# RockChip_RK3588 register map
Vendor: RockChip Electronics Co., Ltd.; Series: RK3588; File version: 0.1
Registers are 32-bit, read-write, no defined reset value unless marked. A register's access mark holds for its fields unless they carry their own. Offsets are from the block's base; [hi:lo] are bit positions; {n}, {i} and the like mark numbered series.

## IOC_PMU2
Base 0xFD5F4000
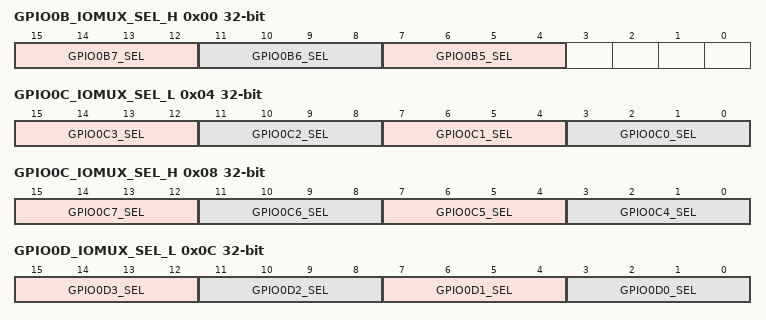
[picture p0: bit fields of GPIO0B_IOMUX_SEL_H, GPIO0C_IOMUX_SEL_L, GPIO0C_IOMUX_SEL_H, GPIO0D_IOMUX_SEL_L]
0x00 GPIO0B_IOMUX_SEL_H — GPIO0B IOMUX Select High bits
  [15:12] GPIO0B7_SEL
    0=GPIO; 1=I2S1_LRCK_M1; 3=PWM0_M0; 8=BUS_IOC_GPIO0B_IOMUX_SEL_H (Refer to BUS_IOC.GPIO0B_IOMUX_SEL_H)
  [11:8] GPIO0B6_SEL
    0=GPIO; 1=I2S1_SCLK_M1; 2=JTAG_TMS_M2; 8=BUS_IOC_GPIO0B_IOMUX_SEL_H (Refer to BUS_IOC.GPIO0B_IOMUX_SEL_H)
  [7:4] GPIO0B5_SEL
    0=GPIO; 1=I2S1_MCLK_M1; 2=JTAG_TCK_M2; 8=BUS_IOC_GPIO0B_IOMUX_SEL_H (Refer to BUS_IOC.GPIO0B_IOMUX_SEL_H)
0x04 GPIO0C_IOMUX_SEL_L — GPIO0C IOMUX Select Low bits
  [15:12] GPIO0C3_SEL
    0=GPIO; 1=PMIC_SLEEP5
  [11:8] GPIO0C2_SEL
    0=GPIO; 1=PMIC_SLEEP4
  [7:4] GPIO0C1_SEL
    0=GPIO; 1=PMIC_SLEEP3
  [3:0] GPIO0C0_SEL
    0=GPIO; 2=PDM0_CLK0_M1; 3=PWM1_M0; 8=BUS_IOC_GPIO0C_IOMUX_SEL_L (Refer to BUS_IOC.GPIO0C_IOMUX_SEL_L)
0x08 GPIO0C_IOMUX_SEL_H — GPIO0C IOMUX Select High bits
  [15:12] GPIO0C7_SEL
    0=GPIO; 1=I2S1_SDI2_M1; 2=PDM0_SDI0_M1; 8=BUS_IOC_GPIO0C_IOMUX_SEL_H (Refer to BUS_IOC.GPIO0C_IOMUX_SEL_H)
  [11:8] GPIO0C6_SEL
    0=GPIO; 1=I2S1_SDI1_M1; 2=NPU_AVS; 4=UART0_RTSN; 8=BUS_IOC_GPIO0C_IOMUX_SEL_H (Refer to BUS_IOC.GPIO0C_IOMUX_SEL_H)
  [7:4] GPIO0C5_SEL
    0=GPIO; 1=I2S1_SDI0_M1; 2=GPU_AVS; 4=UART0_TX_M0; 8=BUS_IOC_GPIO0C_IOMUX_SEL_H (Refer to BUS_IOC.GPIO0C_IOMUX_SEL_H)
  [3:0] GPIO0C4_SEL
    0=GPIO; 2=PDM0_CLK1_M1; 3=PWM2_M0; 4=UART0_RX_M0; 8=BUS_IOC_GPIO0C_IOMUX_SEL_H (Refer to BUS_IOC.GPIO0C_IOMUX_SEL_H)
0x0C GPIO0D_IOMUX_SEL_L — GPIO0D IOMUX Select Low bits
  [15:12] GPIO0D3_SEL
    0=GPIO; 1=LITCPU_AVS; 8=BUS_IOC_GPIO0D_IOMUX_SEL_L (Refer to BUS_IOC.GPIO0D_IOMUX_SEL_L)
  [11:8] GPIO0D2_SEL
    0=GPIO; 1=I2S1_SDO1_M1; 3=I2C0_SDA_M2; 8=BUS_IOC_GPIO0D_IOMUX_SEL_L (Refer to BUS_IOC.GPIO0D_IOMUX_SEL_L)
  [7:4] GPIO0D1_SEL
    0=GPIO; 1=I2S1_SDO0_M1; 2=CPU_BIG0_AVS; 3=I2C0_SCL_M2; 4=UART0_CTSN; 8=BUS_IOC_GPIO0D_IOMUX_SEL_L (Refer to BUS_IOC.GPIO0D_IOMUX_SEL_L)
  [3:0] GPIO0D0_SEL
    0=GPIO; 1=I2S1_SDI3_M1; 2=PDM0_SDI1_M1; 8=BUS_IOC_GPIO0D_IOMUX_SEL_L (Refer to BUS_IOC.GPIO0D_IOMUX_SEL_L)
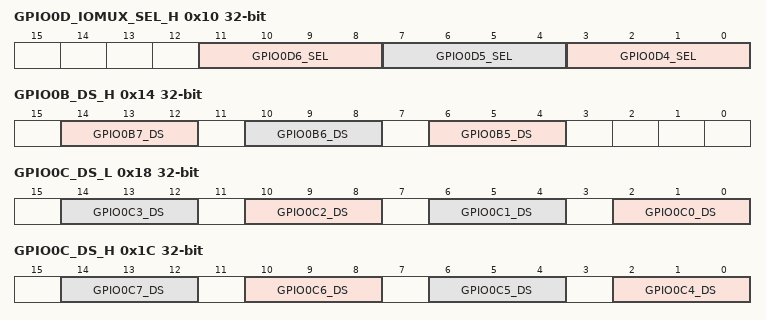
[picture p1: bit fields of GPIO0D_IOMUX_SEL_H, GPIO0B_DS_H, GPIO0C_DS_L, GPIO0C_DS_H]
0x10 GPIO0D_IOMUX_SEL_H — GPIO0D IOMUX Select High bits
  [11:8] GPIO0D6_SEL
    0=GPIO; 1=PMIC_SLEEP6; 2=PDM0_SDI3_M1
  [7:4] GPIO0D5_SEL
    0=GPIO; 1=I2S1_SDO3_M1; 2=CPU_BIG1_AVS; 8=BUS_IOC_GPIO0D_IOMUX_SEL_H (Refer to BUS_IOC.GPIO0D_IOMUX_SEL_H)
  [3:0] GPIO0D4_SEL
    0=GPIO; 1=I2S1_SDO2_M1; 2=PDM0_SDI2_M1; 3=PWM3_IR_M0; 8=BUS_IOC_GPIO0D_IOMUX_SEL_H (Refer to BUS_IOC.GPIO0D_IOMUX_SEL_H)
0x14 GPIO0B_DS_H — GPIO0B Driver Strength Control High bits
  [all] fields
    0=100OHM; 4=66OHM; 2=50OHM; 6=40OHM; 1=33OHM; 5=25OHM
  [14:12] GPIO0B7_DS — GPIO0B7 DS control Driver Strength Selection
  [10:8] GPIO0B6_DS — GPIO0B6 DS control Driver Strength Selection
  [6:4] GPIO0B5_DS — GPIO0B5 DS control Driver Strength Selection
0x18 GPIO0C_DS_L — GPIO0C Driver Strength Control Low bits
  [all] fields
    0=100OHM; 4=66OHM; 2=50OHM; 6=40OHM; 1=33OHM; 5=25OHM
  [4n+2:4n] GPIO0C{n}_DS (n=0..3) — GPIO0C{n} DS control Driver Strength Selection
0x1C GPIO0C_DS_H — GPIO0C Driver Strength Control High bits
  [all] fields
    0=100OHM; 4=66OHM; 2=50OHM; 6=40OHM; 1=33OHM; 5=25OHM
  [4n-14:4n-16] GPIO0C{n}_DS (n=4..7) — GPIO0C{n} DS control Driver Strength Selection
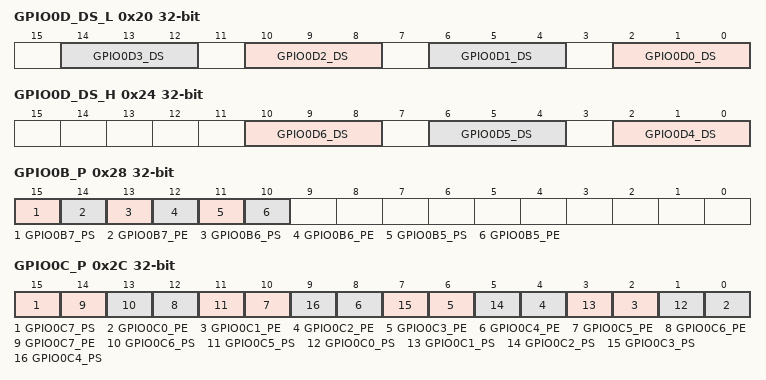
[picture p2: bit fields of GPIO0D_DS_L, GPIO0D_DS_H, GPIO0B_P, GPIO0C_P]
0x20 GPIO0D_DS_L — GPIO0D Driver Strength Control Low bits
  [all] fields
    0=100OHM; 4=66OHM; 2=50OHM; 6=40OHM; 1=33OHM; 5=25OHM
  [4n+2:4n] GPIO0D{n}_DS (n=0..3) — GPIO0D{n} DS control Driver Strength Selection
0x24 GPIO0D_DS_H — GPIO0D Driver Strength Control High bits
  [all] fields
    0=100OHM; 4=66OHM; 2=50OHM; 6=40OHM; 1=33OHM; 5=25OHM
  [10:8] GPIO0D6_DS — GPIO0D6 DS control Driver Strength Selection
  [6:4] GPIO0D5_DS — GPIO0D5 DS control Driver Strength Selection
  [2:0] GPIO0D4_DS — GPIO0D4 DS control Driver Strength Selection
0x28 GPIO0B_P — GPIO0B Pull-up/down Control
  [15] GPIO0B7_PS — GPIO0B7 PS control Weak PU/PD Resistor Selection
    0=PD_SELECTION; 1=PU_SELECTION
  [14] GPIO0B7_PE — GPIO0B7 PE control Active High Weak PU/PD Resistor Enable
    0=PU_PD_DISABLE; 1=PU_PD_ENABLE
  [13] GPIO0B6_PS — GPIO0B6 PS control Weak PU/PD Resistor Selection
    0=PD_SELECTION; 1=PU_SELECTION
  [12] GPIO0B6_PE — GPIO0B6 PE control Active High Weak PU/PD Resistor Enable
    0=PU_PD_DISABLE; 1=PU_PD_ENABLE
  [11] GPIO0B5_PS — GPIO0B5 PS control Weak PU/PD Resistor Selection
    0=PD_SELECTION; 1=PU_SELECTION
  [10] GPIO0B5_PE — GPIO0B5 PE control Active High Weak PU/PD Resistor Enable
    0=PU_PD_DISABLE; 1=PU_PD_ENABLE
0x2C GPIO0C_P — GPIO0C Pull-up/down Control
  [15] GPIO0C7_PS — GPIO0C7 PS control Weak PU/PD Resistor Selection
    0=PD_SELECTION; 1=PU_SELECTION
  [2n] GPIO0C{n}_PE (n=0..7) — GPIO0C{n} PE control Active High Weak PU/PD Resistor Enable
    0=PU_PD_DISABLE; 1=PU_PD_ENABLE
  [13] GPIO0C6_PS — GPIO0C6 PS control Weak PU/PD Resistor Selection
    0=PD_SELECTION; 1=PU_SELECTION
  [11] GPIO0C5_PS — GPIO0C5 PS control Weak PU/PD Resistor Selection
    0=PD_SELECTION; 1=PU_SELECTION
  [2n+1] GPIO0C{n}_PS (n=0..4) — GPIO0C{n} PS control Weak PU/PD Resistor Selection
    0=PD_SELECTION; 1=PU SELECTION
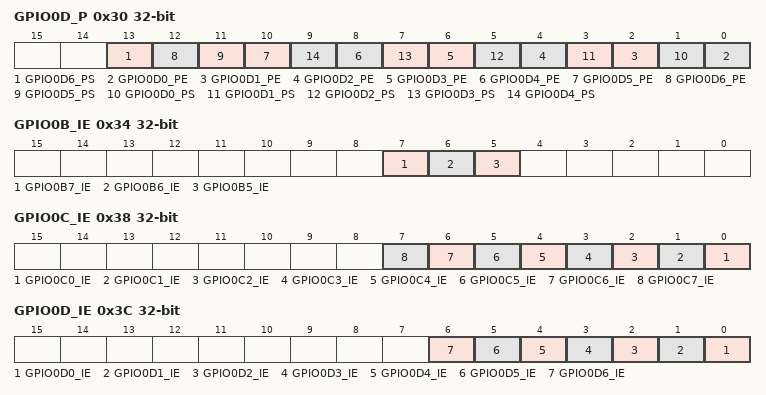
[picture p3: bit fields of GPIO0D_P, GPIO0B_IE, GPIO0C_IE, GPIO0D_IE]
0x30 GPIO0D_P — GPIO0D Pull-up/down Control
  [13] GPIO0D6_PS — GPIO0D6 PS control Weak PU/PD Resistor Selection
    0=PD_SELECTION; 1=PU_SELECTION
  [2n] GPIO0D{n}_PE (n=0..6) — GPIO0D{n} PE control Active High Weak PU/PD Resistor Enable
    0=PU_PD_DISABLE; 1=PU_PD_ENABLE
  [11] GPIO0D5_PS — GPIO0D5 PS control Weak PU/PD Resistor Selection
    0=PD_SELECTION; 1=PU_SELECTION
  [2n+1] GPIO0D{n}_PS (n=0..4) — GPIO0D{n} PS control Weak PU/PD Resistor Selection
    0=PD_SELECTION; 1=PU SELECTION
0x34 GPIO0B_IE — GPIO0B Input Enable Control
  [all] fields
    1=ENABLE; 0=DISABLE
  [7] GPIO0B7_IE — GPIO0B7 IE control Active High input buffer enable
  [6] GPIO0B6_IE — GPIO0B6 IE control Active High input buffer enable
  [5] GPIO0B5_IE — GPIO0B5 IE control Active High input buffer enable
0x38 GPIO0C_IE — GPIO0C Input Enable Control
  [all] fields
    1=ENABLE; 0=DISABLE
  [n] GPIO0C{n}_IE (n=0..7) — GPIO0C{n} IE control Active High input buffer enable
0x3C GPIO0D_IE — GPIO0D Input Enable Control
  [all] fields
    1=ENABLE; 0=DISABLE
  [n] GPIO0D{n}_IE (n=0..6) — GPIO0D{n} IE control Active High input buffer enable
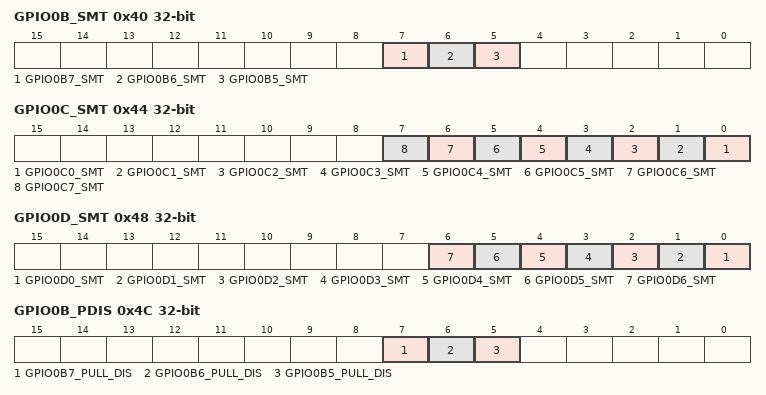
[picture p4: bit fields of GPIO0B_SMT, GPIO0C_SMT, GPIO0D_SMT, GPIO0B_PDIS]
0x40 GPIO0B_SMT — GPIO0B Schmitt Trigger Control
  [all] fields
    0=CMOS; 1=SCHMITT_TRIGGER
  [7] GPIO0B7_SMT — GPIO0B7 SMT control CMOS/Schmitt Trigger Selection
  [6] GPIO0B6_SMT — GPIO0B6 SMT control CMOS/Schmitt Trigger Selection
  [5] GPIO0B5_SMT — GPIO0B5 SMT control CMOS/Schmitt Trigger Selection
0x44 GPIO0C_SMT — GPIO0C Schmitt Trigger Control
  [all] fields
    0=CMOS; 1=SCHMITT_TRIGGER
  [n] GPIO0C{n}_SMT (n=0..7) — GPIO0C{n} SMT control CMOS/Schmitt Trigger Selection
0x48 GPIO0D_SMT — GPIO0D Schmitt Trigger Control
  [all] fields
    0=CMOS; 1=SCHMITT_TRIGGER
  [n] GPIO0D{n}_SMT (n=0..6) — GPIO0D{n} SMT control CMOS/Schmitt Trigger Selection
0x4C GPIO0B_PDIS — GPIO0B Auto Pull-up/down disable Control
  [7] GPIO0B7_PULL_DIS
    1=DISABLE (disable GPIO0B7 pull up/down when output enable)
  [6] GPIO0B6_PULL_DIS
    1=DISABLE (disable GPIO0B6 pull up/down when output enable)
  [5] GPIO0B5_PULL_DIS
    1=DISABLE (disable GPIO0B5 pull up/down when output enable)
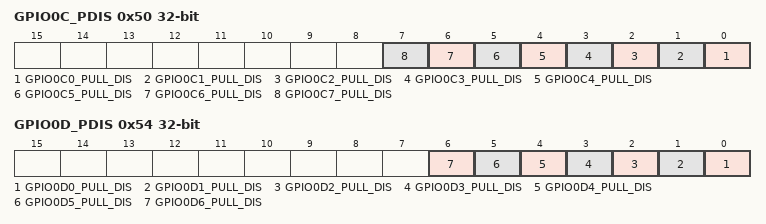
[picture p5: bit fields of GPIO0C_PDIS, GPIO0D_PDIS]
0x50 GPIO0C_PDIS — GPIO0C Auto Pull-up/down disable Control
  [n] GPIO0C{n}_PULL_DIS (n=0..7)
    1=DISABLE (disable GPIO0C{n} pull up/down when output enable)
0x54 GPIO0D_PDIS — GPIO0D Auto Pull-up/down disable Control
  [n] GPIO0D{n}_PULL_DIS (n=0..6)
    1=DISABLE (disable GPIO0D{n} pull up/down when output enable)
